# S1C31W74 register map
Vendor: Epson; Series: S1C31W74; File version: 1.11
CPU: CM0PLUS r0p1, little endian, MPU, no FPU, VTOR, 2 interrupt priority bits
Registers are 16-bit, read-write, reset 0x0 unless marked. A register's access mark holds for its fields unless they carry their own. Offsets are from the block's base; [hi:lo] are bit positions; {n}, {i} and the like mark numbered series; 'fields as' and 'values as' point back to an identical list.

## LCD32B — LCD Driver control
Base 0x40000800
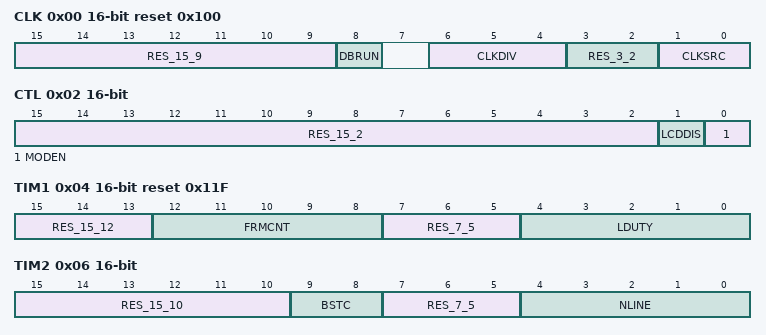
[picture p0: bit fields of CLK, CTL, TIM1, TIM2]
0x00 CLK reset 0x100 — Clock Control Register
  [15:9] RES_15_9 ro — Reserved bits
  [8] DBRUN — Enable clock on debug mode
    0=STOP (Debug stop); 1=RUN (Debug run)
  [6:4] CLKDIV — Clock division select (can be write protected)
  [3:2] RES_3_2 ro — Reserved bits
  [1:0] CLKSRC — Clock source select (can be write protected)
    0=IOSC; 1=OSC1; 2=OSC3; 3=EXOSC
0x02 CTL — Control Register
  [15:2] RES_15_2 ro — Reserved bits
  [1] LCDDIS — LCDIO discharge enable
    0=DISABLE; 1=ENABLE
  [0] MODEN — LCD enable
    0=DISABLE; 1=ENABLE
0x04 TIM1 reset 0x11F — Timing Control Register 1
  [15:13] RES_15_12 ro — Reserved bits
  [12:8] FRMCNT — Frame frequency control, FRMCNT=(1/8)xfLCLKx(duty)x(1/FR)-1
  [7:5] RES_7_5 ro — Reserved bits
  [4:0] LDUTY — Duty select control, duty=1/(LDUTY+1)
0x06 TIM2 — Timing Control Register 2
  [15:10] RES_15_10 ro — Reserved bits
  [9:8] BSTC — Booster clock control
    0=DIV_4 (Booster clock frequency = fLCLK/4); 1=DIV_16 (Booster clock frequency = fLCLK/16); 2=DIV_32 (Booster clock frequency = fLCLK/32); 3=DIV_64 (Booster clock frequency = fLCLK/64)
  [7:5] RES_7_5 ro — Reserved bits
  [4:0] NLINE — SEG n line reverse drive selection
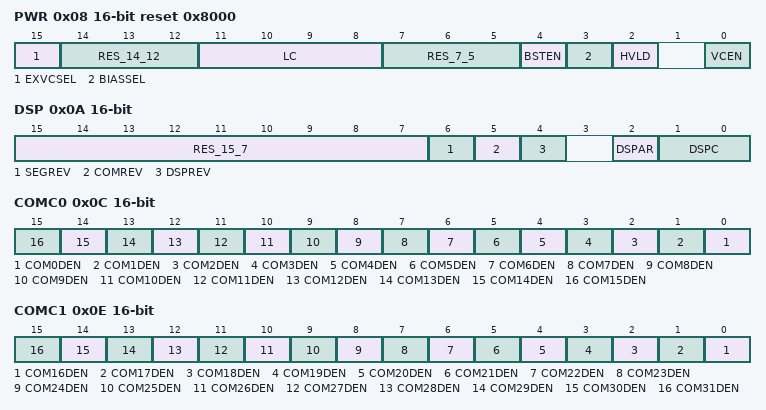
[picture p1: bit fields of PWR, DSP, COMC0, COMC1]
0x08 PWR reset 0x8000 — Power Control Register
  [15] EXVCSEL — External/Internal mode select
    0=Internal mode select; 1=External mode select
  [14:12] RES_14_12 ro — Reserved bits
  [11:8] LC — LCD contrast adjust
  [7:5] RES_7_5 ro — Reserved bits
  [4] BSTEN — LCD booster enable
    0=DISABLE; 1=ENABLE
  [3] BIASSEL — BIAS select
  [2] HVLD — LCD heavy load protection mode
    0=DISABLE; 1=ENABLE
  [0] VCEN — LCD voltage regulator enable
    0=DISABLE; 1=ENABLE
0x0A DSP — Display Control Register
  [15:7] RES_15_7 ro — Reserved bits
  [6] SEGREV — Segment output assignment control
    0=REVERSED (Inverse assignment); 1=NORMAL (Normal assignment)
  [5] COMREV — Common output assignment control
    values as SEGREV
  [4] DSPREV — Display reverse control
    0=REVERSED (Inverted display); 1=NORMAL (Normal display)
  [2] DSPAR — Display memory area control
    0=AREA0 (Display area 0); 1=AREA0 (Display area 1)
  [1:0] DSPC — LCD display control
    0=DISP_OFF (Display off); 1=NORMAL (Normal display); 2=ALL_ON; 3=ALL_OFF (All off (static drive))
0x0C COMC0 — COM Terminal Control Register 0
  [all] fields
    0=DISABLE; 1=ENABLE
  [n] COM{n}DEN (n=0..15) — COM{n} drive enable
0x0E COMC1 — COM Terminal Control Register 1
  [all] fields
    0=DISABLE; 1=ENABLE
  [n-16] COM{n}DEN (n=16..31) — COM{n} drive enable
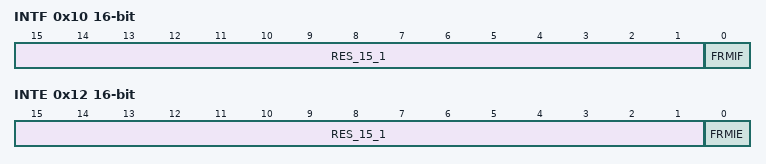
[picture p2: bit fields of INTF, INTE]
0x10 INTF — Interrupt Flag Register
  [15:1] RES_15_1 ro — Reserved bits
  [0] FRMIF write-1-clears — Frame signal interrupt flag
    0=NOT_OCCURED (No cause of interrupt occurred); 1=OCCURED (Cause of interrupt occurred)
0x12 INTE — Interrupt Enable Register
  [15:1] RES_15_1 ro — Reserved bits
  [0] FRMIE — Frame signal interrupt enable
    0=DISABLE; 1=ENABLE

## RFC_0
Base 0x40000840
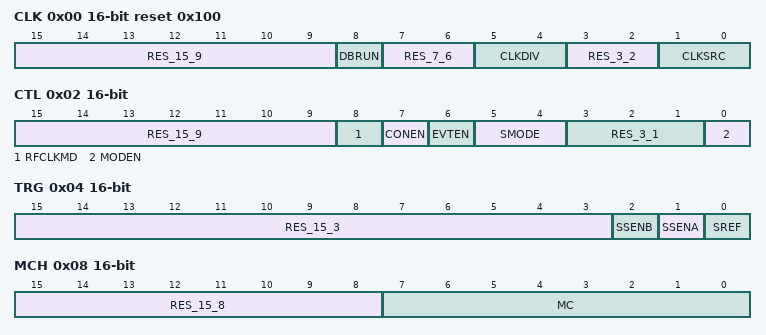
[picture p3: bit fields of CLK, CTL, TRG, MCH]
0x00 CLK reset 0x100 — Clock Control Register
  [15:9] RES_15_9 ro — Reserved
  [8] DBRUN — Enable clock on debug mode
    0=DISABLE; 1=ENABLE
  [7:6] RES_7_6 ro — Reserved
  [5:4] CLKDIV — Clock division select (can be write protected)
  [3:2] RES_3_2 ro — Reserved
  [1:0] CLKSRC — TC clock source select (can be write protected)
    0=IOSC; 1=OSC1; 2=OSC3; 3=EXOSC
0x02 CTL — RFC Control Register
  [15:9] RES_15_9 ro — Reserved bits
  [8] RFCLKMD — RFCLKO output mode select
  [7] CONEN — Continuous oscillation enable
  [6] EVTEN — Enable/Disable external clock input mode
  [5:4] SMODE — Sensor oscillation MODE select
  [3:1] RES_3_1 ro — VenT counter mode Enable
  [0] MODEN — Enable/Disable RFC operations
0x04 TRG — Oscillation Trigger Register
  [15:3] RES_15_3 ro — Reserved bits
  [2] SSENB — Sensor B oscillation start trigger
  [1] SSENA — Sensor A oscillation start trigger
  [0] SREF — Test mode enable
0x06 MCL — Measurement Counter Low Register)
  [15:0] MC — MC[15:0]Measurement Counter data
0x08 MCH — Measurement Counter High Register)
  [15:8] RES_15_8 ro — Reserved bits
  [7:0] MC — MC[23:16]Measurement Counter data
0x0A TCL — Time Base Counter Low Register)
  [15:0] TC — TC[15:0] Time Base Counter data
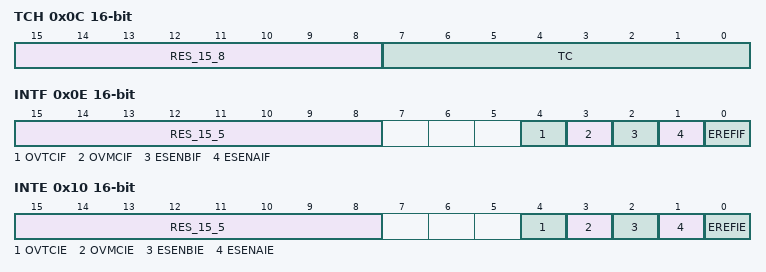
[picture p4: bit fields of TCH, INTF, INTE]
0x0C TCH — Time Base Counter High Register)
  [15:8] RES_15_8 ro — Reserved bits
  [7:0] TC — TC[23:16]Time Base Counter data
0x0E INTF — Interrupt Flag Register
  [15:8] RES_15_5 ro — Reserved bits
  [4] OVTCIF ro — Time base Counter OVer flow error Int Flag
  [3] OVMCIF ro — Measurement Counter Overflow error Int Flag Resister
  [2] ESENBIF ro — SENsor B oscillation End Int Flag
  [1] ESENAIF ro — SENsor A oscillation End Int Flag
  [0] EREFIF ro — REFerence oscillation End flag Int Flag
0x10 INTE — Interrupt Enable Register)
  [15:8] RES_15_5 ro — Reserved bits
  [4] OVTCIE — Time base Counter OVer flow error Int enable
  [3] OVMCIE — Measurement Counter Overflow error Int enable Resister
  [2] ESENBIE — SENsor B oscillation End Int enable
  [1] ESENAIE — SENsor A oscillation End Int Flag
  [0] EREFIE — REFerence oscillation End flag Int Flag

## USBMISC — USB MISC Controller
Base 0x40000970
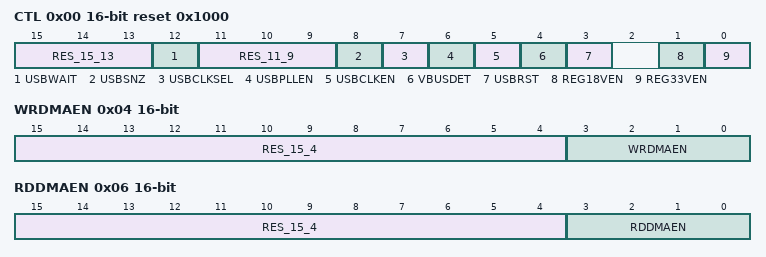
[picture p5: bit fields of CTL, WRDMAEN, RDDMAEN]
0x00 CTL reset 0x1000 — Misc Control Register
  [15:13] RES_15_13 ro — Reserved bits
  [12] USBWAIT — Wait cycle control
  [11:9] RES_11_9 ro — Reserved bits
  [8] USBSNZ — USB snooze control enable
    0=DISABLE; 1=ENABLE
  [7] USBCLKSEL — USB clock source select
    0=PLL; 1=USBOSC
  [6] USBPLLEN — PLL operation enable
    0=DISABLE; 1=ENABLE
  [5] USBCLKEN — USB logic circuits clock supply enable
    0=DISABLE; 1=ENABLE
  [4] VBUSDET — USB controller communication enable after VBUS is detected
    0=DISABLE; 1=ENABLE
  [3] USBRST — Reset state control
    0=RESET (Puts USB logic circuits into RESET state); 1=RELEASE (Release USB logic circuits from RESET state)
  [1] REG18VEN — 1.8 V regulator enable for the USB logic circuits
    0=DISABLE; 1=ENABLE
  [0] REG33VEN — 3.3 V regulator enable for the PHY part
    0=DISABLE; 1=ENABLE
0x04 WRDMAEN — USB FIFO Write DMA Request Enable Register
  [15:4] RES_15_4 ro — Reserved bits
  [3:0] WRDMAEN — USB FIFO Write DMA Request Enable Register
0x06 RDDMAEN — USB FIFO Read DMA Request Enable Register
  [15:4] RES_15_4 ro — Reserved bits
  [3:0] RDDMAEN — USB FIFO DMA request enable
